AUTOSAR XML (schema 00051)
package /ComponentTypes
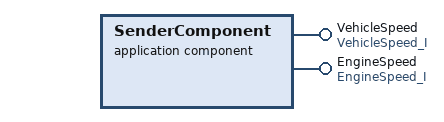
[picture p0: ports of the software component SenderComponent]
  application sw component type SenderComponent
    provide port VehicleSpeed: nonqueued-sender-com-spec{data-element=VehicleSpeed, init-value=constant-reference=VehicleSpeed_IV}, provided-interface=VehicleSpeed_I
    provide port EngineSpeed: nonqueued-sender-com-spec{data-element=EngineSpeed, init-value=constant-reference=EngineSpeed_IV}, provided-interface=EngineSpeed_I
    behavior SenderComponent_InternalBehavior
  swc implementation SenderComponent_Implementation: behavior=SenderComponent_InternalBehavior
